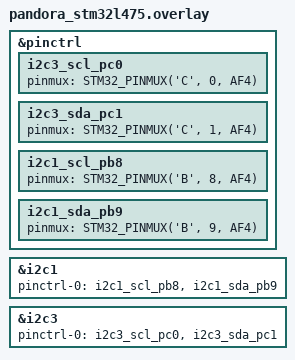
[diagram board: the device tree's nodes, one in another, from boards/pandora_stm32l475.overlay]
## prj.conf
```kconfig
CONFIG_PRINTK=y
CONFIG_SHELL=y
CONFIG_LOG=y
CONFIG_INIT_STACKS=y
CONFIG_THREAD_STACK_INFO=y
CONFIG_KERNEL_SHELL=y
CONFIG_THREAD_MONITOR=y
CONFIG_BOOT_BANNER=n
CONFIG_THREAD_NAME=y
CONFIG_DEVICE_SHELL=y
CONFIG_POSIX_CLOCK=y
CONFIG_DATE_SHELL=y
CONFIG_THREAD_RUNTIME_STATS=y
CONFIG_THREAD_RUNTIME_STATS_USE_TIMING_FUNCTIONS=y
CONFIG_STATS=y
CONFIG_STATS_SHELL=y
CONFIG_I2C_SHELL=y
CONFIG_I2C=y
```

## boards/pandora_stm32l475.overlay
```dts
/*
 * Copyright (c) 2023 Łukasz Hejnak (LeHack) <lehack-ghub@lehack.pl>
 *
 * SPDX-License-Identifier: Apache-2.0
 */


&pinctrl {
	i2c3_scl_pc0: i2c3_scl_pc0 {
		pinmux = <STM32_PINMUX('C', 0, AF4)>;
	};
	i2c3_sda_pc1: i2c3_sda_pc1 {
		pinmux = <STM32_PINMUX('C', 1, AF4)>;
	};
	i2c1_scl_pb8: i2c1_scl_pb8 {
		pinmux = <STM32_PINMUX('B', 8, AF4)>;
	};
	i2c1_sda_pb9: i2c1_sda_pb9 {
		pinmux = <STM32_PINMUX('B', 9, AF4)>;
	};
};


&i2c1 {
	status = "okay";
	pinctrl-names = "default";
	pinctrl-0 = <&i2c1_scl_pb8 &i2c1_sda_pb9>;
};

&i2c3 {
	status = "okay";
	pinctrl-names = "default";
	pinctrl-0 = <&i2c3_scl_pc0 &i2c3_sda_pc1>;
};
```

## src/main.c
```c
/*
 * Copyright (c) 2015 Intel Corporation
 *
 * SPDX-License-Identifier: Apache-2.0
 */

#include <zephyr/kernel.h>
#include <zephyr/shell/shell.h>
#include <version.h>
#include <zephyr/logging/log.h>

LOG_MODULE_REGISTER(app);

int main()
{
	LOG_INF("I2C Scan! %s\n", CONFIG_BOARD);
	return 0;
}
```
